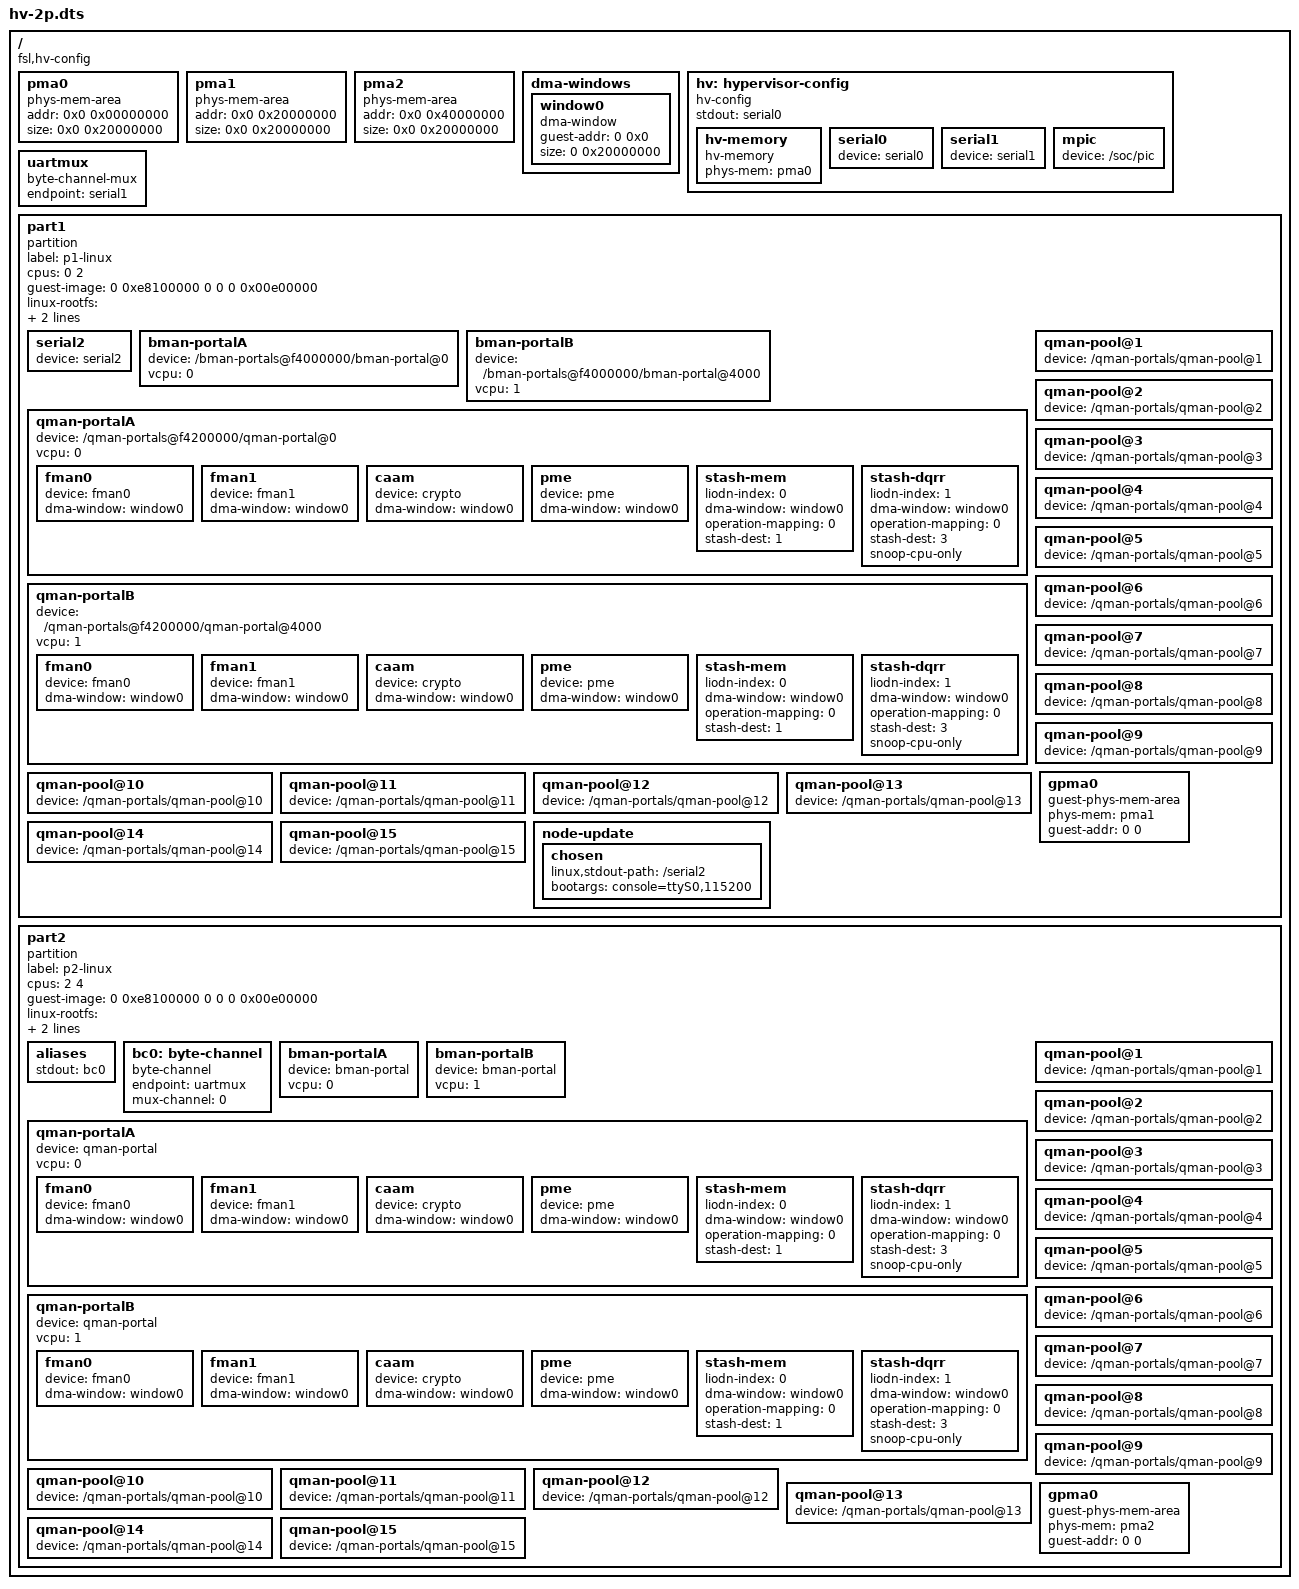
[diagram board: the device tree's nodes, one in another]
/dts-v1/;

/ {
	compatible = "fsl,hv-config";

	// =====================================================
	// Physical Memory Areas
	// =====================================================
	pma0:pma0 {
		compatible = "phys-mem-area";
		addr = <0x0 0x00000000>;
		size = <0x0 0x20000000>;  // 512MB
	};

	pma1:pma1 {
		compatible = "phys-mem-area";
		addr = <0x0 0x20000000>;
		size = <0x0 0x20000000>;  // 512MB
	};

	pma2:pma2 {
		compatible = "phys-mem-area";
		addr = <0x0 0x40000000>;
		size = <0x0 0x20000000>;  // 512MB
	};

	dma-windows {
		window0: window0 {
			compatible = "dma-window";
			guest-addr = <0 0x0>;
			size = <0 0x20000000>;
		};
	};

	// =====================================================
	// Hypervisor Config
	// =====================================================
	hv:hypervisor-config {
		compatible = "hv-config";
		stdout = <&serial0>;

		hv-memory {
			compatible = "hv-memory";
			phys-mem = <&pma0>;
		};

		serial0:serial0 {
			device = "serial0";
		};

		serial1:serial1 {
			device = "serial1";
		};

		mpic {
			device = "/soc/pic";
		};
	};

	uartmux: uartmux {
		compatible = "byte-channel-mux";
		endpoint = <&serial1>;
	};

	part1 {
		compatible = "partition";
		label = "p1-linux";
		cpus = <0 2>;
		guest-image = <0 0xe8100000 0 0 0 0x00e00000>;
		linux-rootfs = <0 0xe9000000 0 0x01300000 0 0x00800000>;
		dtb-window = <0 0x1000000 0 0x10000>;

		serial2 {
			device = "serial2";
		};

		bman-portalA {
			device = "/bman-portals@f4000000/bman-portal@0";
			vcpu = <0>;
		};

		bman-portalB {
			device = "/bman-portals@f4000000/bman-portal@4000";
			vcpu = <1>;
		};

		qman-portalA {
			device = "/qman-portals@f4200000/qman-portal@0";
			vcpu = <0>;
			fman0 {
				device = "fman0";
				dma-window = <&window0>;
			};
			fman1 {
				device = "fman1";
				dma-window = <&window0>;
			};
			caam {
				device = "crypto";
				dma-window = <&window0>;
			};
			pme {
				device = "pme";
				dma-window = <&window0>;
			};
			stash-mem {
				liodn-index = <0>;
				dma-window = <&window0>;
				operation-mapping = <0>;  // OMI_QMAN
				stash-dest = <1>;
			};
			stash-dqrr {
				liodn-index = <1>;
				dma-window = <&window0>;
				operation-mapping = <0>;  // OMI_QMAN
				stash-dest = <3>;
				snoop-cpu-only;
			};

		};

		qman-portalB {
			device = "/qman-portals@f4200000/qman-portal@4000";
			vcpu = <1>;
			fman0 {
				device = "fman0";
				dma-window = <&window0>;
			};
			fman1 {
				device = "fman1";
				dma-window = <&window0>;
			};
			caam {
				device = "crypto";
				dma-window = <&window0>;
			};
			pme {
				device = "pme";
				dma-window = <&window0>;
			};
			stash-mem {
				liodn-index = <0>;
				dma-window = <&window0>;
				operation-mapping = <0>;  // OMI_QMAN
				stash-dest = <1>;
			};
			stash-dqrr {
				liodn-index = <1>;
				dma-window = <&window0>;
				operation-mapping = <0>;  // OMI_QMAN
				stash-dest = <3>;
				snoop-cpu-only;
			};
		};

		qman-pool@1 {
			device = "/qman-portals/qman-pool@1";
		};

		qman-pool@2 {
			device = "/qman-portals/qman-pool@2";
		};

		qman-pool@3 {
			device = "/qman-portals/qman-pool@3";
		};

		qman-pool@4 {
			device = "/qman-portals/qman-pool@4";
		};

		qman-pool@5 {
			device = "/qman-portals/qman-pool@5";
		};

		qman-pool@6 {
			device = "/qman-portals/qman-pool@6";
		};

		qman-pool@7 {
			device = "/qman-portals/qman-pool@7";
		};

		qman-pool@8 {
			device = "/qman-portals/qman-pool@8";
		};

		qman-pool@9 {
			device = "/qman-portals/qman-pool@9";
		};

		qman-pool@10 {
			device = "/qman-portals/qman-pool@10";
		};

		qman-pool@11 {
			device = "/qman-portals/qman-pool@11";
		};

		qman-pool@12 {
			device = "/qman-portals/qman-pool@12";
		};

		qman-pool@13 {
			device = "/qman-portals/qman-pool@13";
		};

		qman-pool@14 {
			device = "/qman-portals/qman-pool@14";
		};

		qman-pool@15 {
			device = "/qman-portals/qman-pool@15";
		};

		gpma0 {
			compatible = "guest-phys-mem-area";
			phys-mem = <&pma1>;
			guest-addr = <0 0>;
		};

		node-update {
			chosen {
				/* We should probably provide fixup for linux,stdout-path
				 * similar to aliases.
				 */
				linux,stdout-path = "/serial2";
				bootargs = "console=ttyS0,115200";
			};
		};
	};

	part2 {
		compatible = "partition";
		label = "p2-linux";
		cpus = <2 4>;
		guest-image = <0 0xe8100000 0 0 0 0x00e00000>;
		linux-rootfs = <0 0xe9000000 0 0x01300000 0 0x00800000>;
		dtb-window = <0 0x1000000 0 0x10000>;

		aliases {
			stdout = <&bc0>;
		};

		bc0: byte-channel {
			compatible = "byte-channel";
			endpoint = <&uartmux>;
			mux-channel = <0>;
		};

		bman-portalA {
			device = "bman-portal";
			vcpu = <0>;
		};

		bman-portalB {
			device = "bman-portal";
			vcpu = <1>;
		};

		qman-portalA {
			device = "qman-portal";
			vcpu = <0>;
			fman0 {
				device = "fman0";
				dma-window = <&window0>;
			};
			fman1 {
				device = "fman1";
				dma-window = <&window0>;
			};
			caam {
				device = "crypto";
				dma-window = <&window0>;
			};
			pme {
				device = "pme";
				dma-window = <&window0>;
			};
			stash-mem {
				liodn-index = <0>;
				dma-window = <&window0>;
				operation-mapping = <0>;  // OMI_QMAN
				stash-dest = <1>;
			};
			stash-dqrr {
				liodn-index = <1>;
				dma-window = <&window0>;
				operation-mapping = <0>;  // OMI_QMAN
				stash-dest = <3>;
				snoop-cpu-only;
			};

		};

		qman-portalB {
			device = "qman-portal";
			vcpu = <1>;
			fman0 {
				device = "fman0";
				dma-window = <&window0>;
			};
			fman1 {
				device = "fman1";
				dma-window = <&window0>;
			};
			caam {
				device = "crypto";
				dma-window = <&window0>;
			};
			pme {
				device = "pme";
				dma-window = <&window0>;
			};
			stash-mem {
				liodn-index = <0>;
				dma-window = <&window0>;
				operation-mapping = <0>;  // OMI_QMAN
				stash-dest = <1>;
			};
			stash-dqrr {
				liodn-index = <1>;
				dma-window = <&window0>;
				operation-mapping = <0>;  // OMI_QMAN
				stash-dest = <3>;
				snoop-cpu-only;
			};
		};

		qman-pool@1 {
			device = "/qman-portals/qman-pool@1";
		};

		qman-pool@2 {
			device = "/qman-portals/qman-pool@2";
		};

		qman-pool@3 {
			device = "/qman-portals/qman-pool@3";
		};

		qman-pool@4 {
			device = "/qman-portals/qman-pool@4";
		};

		qman-pool@5 {
			device = "/qman-portals/qman-pool@5";
		};

		qman-pool@6 {
			device = "/qman-portals/qman-pool@6";
		};

		qman-pool@7 {
			device = "/qman-portals/qman-pool@7";
		};

		qman-pool@8 {
			device = "/qman-portals/qman-pool@8";
		};

		qman-pool@9 {
			device = "/qman-portals/qman-pool@9";
		};

		qman-pool@10 {
			device = "/qman-portals/qman-pool@10";
		};

		qman-pool@11 {
			device = "/qman-portals/qman-pool@11";
		};

		qman-pool@12 {
			device = "/qman-portals/qman-pool@12";
		};

		qman-pool@13 {
			device = "/qman-portals/qman-pool@13";
		};

		qman-pool@14 {
			device = "/qman-portals/qman-pool@14";
		};

		qman-pool@15 {
			device = "/qman-portals/qman-pool@15";
		};

		gpma0 {
			compatible = "guest-phys-mem-area";
			phys-mem = <&pma2>;
			guest-addr = <0 0>;
		};
	};
};
